# nrf54lilium_network register map
Vendor: Nordic Semiconductor; Series: nrf54; File version: 1
CPU: CM33 r0p4, little endian, MPU, no FPU, 3 interrupt priority bits, 30 interrupts
Registers are 32-bit, read-write, reset 0x0 unless marked. A register's access mark holds for its fields unless they carry their own. Offsets are from the block's base; [hi:lo] are bit positions; 'fields as' and 'values as' point back to an identical list.

## AAR — Accelerated Address Resolver
Base 0x4100E000
0x00 TASKS_START wo — Start resolving addresses based on IRKs specified in the IRK data structure
  [0] TASKS_START
    1=Trigger task
0x08 TASKS_STOP wo — Stop resolving addresses
  [0] TASKS_STOP
    1=Trigger task
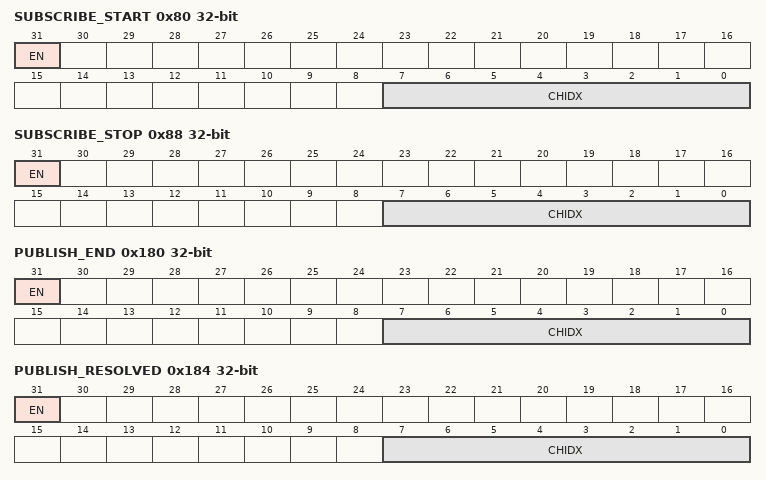
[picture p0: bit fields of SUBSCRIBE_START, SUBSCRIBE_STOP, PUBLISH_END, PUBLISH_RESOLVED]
0x80 SUBSCRIBE_START — Subscribe configuration for task START
  [31] EN
    0=Disabled (Disable subscription); 1=Enabled (Enable subscription)
  [7:0] CHIDX — DPPI channel that task START will subscribe to
0x88 SUBSCRIBE_STOP — Subscribe configuration for task STOP
  [31] EN
    values as SUBSCRIBE_START.EN
  [7:0] CHIDX — DPPI channel that task STOP will subscribe to
0x100 EVENTS_END — Address resolution procedure complete
  [0] EVENTS_END
    0=NotGenerated (Event not generated); 1=Generated (Event generated)
0x104 EVENTS_RESOLVED — Address resolved
  [0] EVENTS_RESOLVED
    values as EVENTS_END.EVENTS_END
0x108 EVENTS_NOTRESOLVED — Address not resolved
  [0] EVENTS_NOTRESOLVED
    values as EVENTS_END.EVENTS_END
0x180 PUBLISH_END — Publish configuration for event END
  [31] EN
    0=Disabled (Disable publishing); 1=Enabled (Enable publishing)
  [7:0] CHIDX — DPPI channel that event END will publish to.
0x184 PUBLISH_RESOLVED — Publish configuration for event RESOLVED
  [31] EN
    values as PUBLISH_END.EN
  [7:0] CHIDX — DPPI channel that event RESOLVED will publish to.
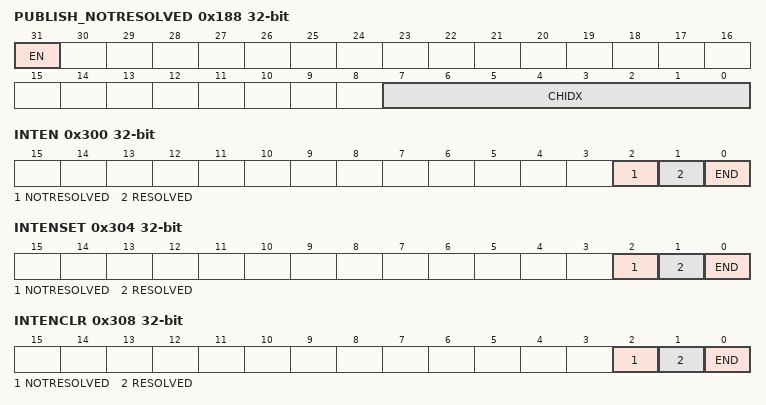
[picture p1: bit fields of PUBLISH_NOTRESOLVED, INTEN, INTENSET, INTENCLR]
0x188 PUBLISH_NOTRESOLVED — Publish configuration for event NOTRESOLVED
  [31] EN
    values as PUBLISH_END.EN
  [7:0] CHIDX — DPPI channel that event NOTRESOLVED will publish to.
0x300 INTEN — Enable or disable interrupt
  [all] fields
    0=Disabled; 1=Enabled
  [2] NOTRESOLVED — Enable or disable interrupt for event NOTRESOLVED
  [1] RESOLVED — Enable or disable interrupt for event RESOLVED
  [0] END — Enable or disable interrupt for event END
0x304 INTENSET — Enable interrupt
  [all] fields
    on read: 0=Disabled (Read: Disabled); 1=Enabled (Read: Enabled) | on write: 1=Set (Enable)
  [2] NOTRESOLVED — Write '1' to enable interrupt for event NOTRESOLVED
  [1] RESOLVED — Write '1' to enable interrupt for event RESOLVED
  [0] END — Write '1' to enable interrupt for event END
0x308 INTENCLR — Disable interrupt
  [all] fields
    on read: 0=Disabled (Read: Disabled); 1=Enabled (Read: Enabled) | on write: 1=Clear (Disable)
  [2] NOTRESOLVED — Write '1' to disable interrupt for event NOTRESOLVED
  [1] RESOLVED — Write '1' to disable interrupt for event RESOLVED
  [0] END — Write '1' to disable interrupt for event END
0x400 STATUS ro — Resolution status
  [3:0] STATUS — The IRK that was used last time an address was resolved
0x500 ENABLE — Enable AAR
  [1:0] ENABLE — Enable or disable AAR
    0=Disabled; 3=Enabled
0x530 INPTR — Pointer to the AAR data structure

## GPIOINTERNAL — GPIO Static
Base 0x418C0500
0xE00 LATCHCLRWAITCNT reset 0x2 — Select the number of wait cycles inserted on the bus when a LATCH register is cleared. Note: this register is only accessible from secure code.
  [1:0] LATCHCLRWAITCNT — Select the number of wait cycles inserted on the bus when a LATCH register is cleared.
0xE04 FORCELDETECTLOWCNT reset 0xF — Select the number of cycles that LDETECT is forced low after clearing a LATCH register. Note: this register is only accessible from secure code.
  [3:0] FORCELDETECTLOWCNT — Select the number of cycles that LDETECT is forced low after clearing a LATCH register.
0xE08 RESET — Reset all GPIO registers. Note: this register is only accessible from secure code.
  [0] RESET — Reset all GPIO registers.
    1=RESET (Trigger reset); 0=NA (No effect)
0xE0C SENSECONFIGCHANGECNT reset 0x3 — Selects the number of cycles before the SENSE configuration takes effect when it is changed. Setting this register lower than the reset value can lead to unwanted LATCH set when SENSE and INPUT fields (PIN_CNF) are changed simultaneously. Note: this register is only accessible from secure code.
  [2:0] SENSECONFIGCHANGECNT — Selects the number of cycles before the SENSE configuration takes effect when it is changed.
